# PIC32MK0512GPK064 device description
Architecture: MIPS; Family: PIC32MK; Series: PIC32MK
Registers are 32-bit, read-write, no defined reset value unless marked. A register's access mark holds for its fields unless they carry their own. Offsets are from the block's base; [hi:lo] are bit positions; lines under a group give offsets from that group; {n}, {i} and the like mark numbered series; 'fields as' and 'values as' point back to an identical list.

## SB
Instances: SB 0x1f8f0510 in periph_ssx
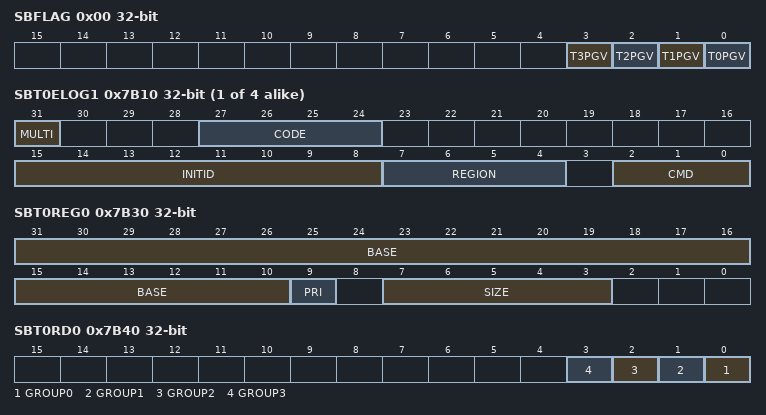
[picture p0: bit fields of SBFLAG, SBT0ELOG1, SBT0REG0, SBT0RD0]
0x00 SBFLAG ro — System Bus Status Flag Register
  [all] fields
    1=Target is reporting a Permission Group (PG) violation; 0=Target is not reporting a PG violation
  [3] T3PGV — Target 3 Permission Group Violation Status bits
  [2] T2PGV — Target 2 Permission Group Violation Status bits
  [1] T1PGV — Target 1Permission Group Violation Status bits
  [0] T0PGV — Target 0 Permission Group Violation Status bits
{0x7B10+0x400*i} SBT{i}ELOG1 ro (i=0..3) — System Bus Target 'x' Error Log Register 1
  [31] MULTI — Multiple Permission Violations Status bit
    1=Multiple errors have been detected; 0=No multiple errors have been detected
  [27:24] CODE — Error Code bits
    3=Permission violation; 0=No error
  [15:8] INITID — Initiator ID of Requester bits
    {v}=CAN{v-9} (v=10..13); 9=USB2; 8=USB1; 7=ADC0-ADC5, ADC7; 5=Flash Controller; 4=DMA Read (DMAPRI (CFGCON) = 1); 3=DMA Read (DMAPRI (CFGCON) = 0); 2=CPU (CPUPRI (CFGCON) = 1); 1=CPU (CPUPRI (CFGCON) = 0)
  [7:4] REGION — Requested Region Number bits
    {v}=Target region {v} reported a permission group violation (v=0..15)
  [2:0] CMD — Transaction Command of the Requester bits
    5=Write (a non-posted write); 3=Read (a locked read caused by a Read-Modify-Write transaction); 2=Read; 1=Write; 0=Idle
{0x7B14+0x400*i} SBT{i}ELOG2 ro (i=0..3) — System Bus Target 'x' Error Log Register 2
  [1:0] GROUP — Requested Permissions Group bits
    1=Group 1; 0=Group 0 (default group of CPU at Reset)
{0x7B18+0x400*i} SBT{i}ECON (i=0..3) — System Bus Target 'x' Error Control Register
  [24] ERRP — Error Control bit
    1=Report protection group violation errors; 0=Do not report protection group violation errors
{0x7B20+0x400*i} SBT{i}ECLRS ro (i=0..3) — System Bus Target 'x' Single Error Clear Register
  [0] CLEAR
{0x7B28+0x400*i} SBT{i}ECLRM ro (i=0..3) — System Bus Target 'x' Multiple Error Clear Register
  [0] CLEAR
0x7B30 SBT0REG0
  [31:10] BASE
  [9] PRI — Region Priority Level bit
    1=Level 2; 0=Level 1
  [7:3] SIZE — Region Size bits
    30=Region size is 549755813888 bytes; 29=Region size is 274877906944 bytes; 28=Region size is 137438953472 bytes; 27=Region size is 68719476736 bytes; 26=Region size is 34359738368 bytes; 25=Region size is 17179869184 bytes; 24=Region size is 8589934592 bytes; 23=Region size is 4294967296 bytes; 22=Region size is 2147483648 bytes; 21=Region size is 1073741824 bytes; 20=Region size is 536870912 bytes; 19=Region size is 268435456 bytes; 18=Region size is 134217728 bytes; 17=Region size is 67108864 bytes; 16=Region size is 33554432 bytes; 15=Region size is 16777216 bytes; 14=Region size is 8388608 bytes; 13=Region size is 4194304 bytes; 12=Region size is 2097152 bytes; 11=Region size is 1048576 bytes; 10=Region size is 524288 bytes; 9=Region size is 262144 bytes; 8=Region size is 131072 bytes; 7=Region size is 65536 bytes; 6=Region size is 32768 bytes; 5=Region size is 16384 bytes; 4=Region size is 8192 bytes; 3=Region size is 4096 bytes; 2=Region size is 2048 bytes; 1=Region size is 1024 bytes; 0=Region is not present
0x7B40 SBT0RD0
  [n] GROUP{n} (n=0..3) — Group{n} Read Permissions bits
    1=Privilege Group {n} has read permission; 0=Privilege Group {n} does not have read permission
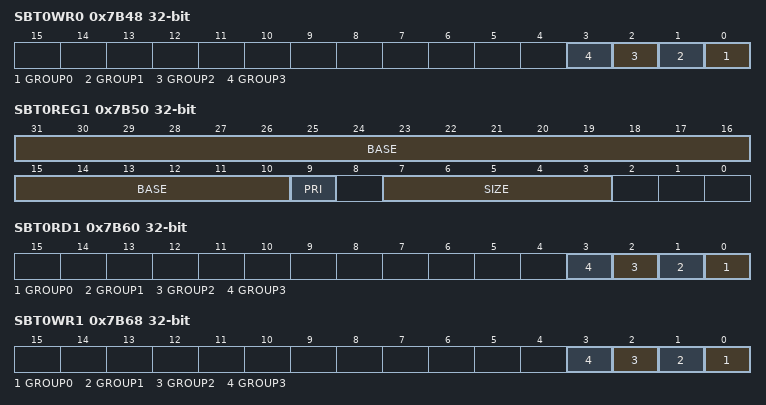
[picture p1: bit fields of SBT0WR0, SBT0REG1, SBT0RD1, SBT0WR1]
0x7B48 SBT0WR0
  [n] GROUP{n} (n=0..3) — Group {n} Write Permissions bits
    1=Privilege Group {n} has write permission; 0=Privilege Group {n} does not have write permission
0x7B50 SBT0REG1
  fields as SBT0REG0
0x7B60 SBT0RD1
  fields as SBT0RD0
0x7B68 SBT0WR1
  fields as SBT0WR0
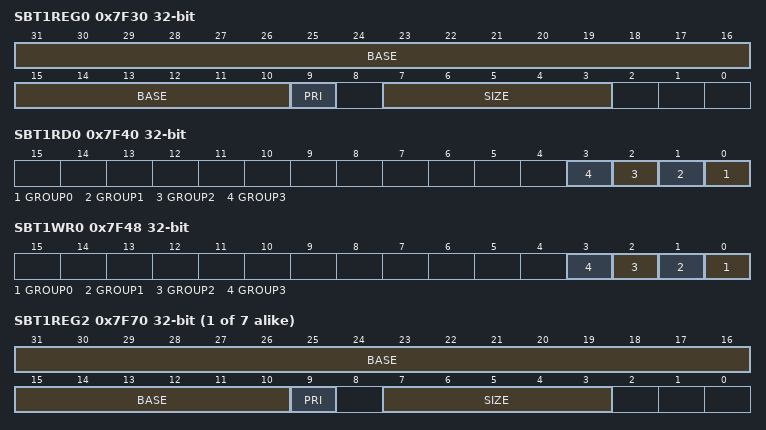
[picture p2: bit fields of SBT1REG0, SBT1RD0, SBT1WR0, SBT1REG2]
0x7F30 SBT1REG0
  fields as SBT0REG0
0x7F40 SBT1RD0
  fields as SBT0RD0
0x7F48 SBT1WR0
  fields as SBT0WR0
{0x7F30+0x20*i} SBT1REG{i} (i=2..8)
  fields as SBT0REG0
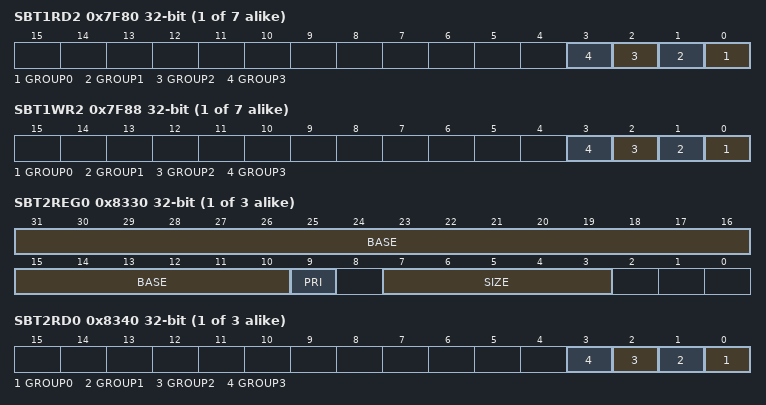
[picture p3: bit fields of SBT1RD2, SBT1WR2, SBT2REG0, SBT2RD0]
{0x7F40+0x20*i} SBT1RD{i} (i=2..8)
  fields as SBT0RD0
{0x7F48+0x20*i} SBT1WR{i} (i=2..8)
  fields as SBT0WR0
{0x8330+0x20*i} SBT2REG{i} (i=0..2)
  fields as SBT0REG0
{0x8340+0x20*i} SBT2RD{i} (i=0..2)
  fields as SBT0RD0
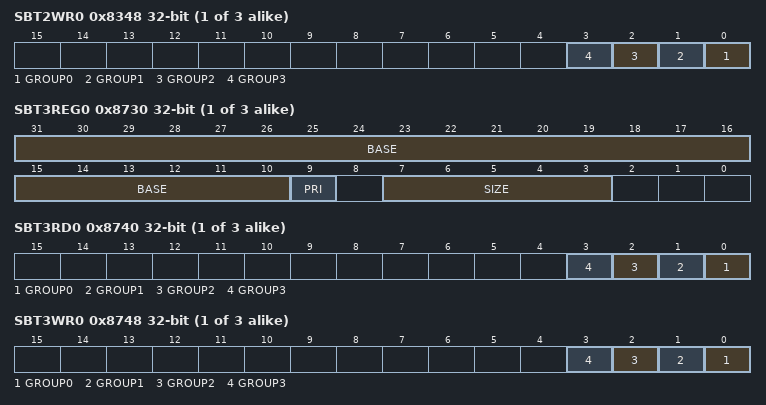
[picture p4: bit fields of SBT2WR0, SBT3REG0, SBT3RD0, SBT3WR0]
{0x8348+0x20*i} SBT2WR{i} (i=0..2)
  fields as SBT0WR0
{0x8730+0x20*i} SBT3REG{i} (i=0..2)
  fields as SBT0REG0
{0x8740+0x20*i} SBT3RD{i} (i=0..2)
  fields as SBT0RD0
{0x8748+0x20*i} SBT3WR{i} (i=0..2)
  fields as SBT0WR0

## Notices in the file
Copyright (c) 2019 Microchip Technology Inc.
SPDX-License-Identifier: Apache-2.0
Licensed under the Apache License, Version 2.0 (the "License");
you may not use this file except in compliance with the License.
You may obtain a copy of the License at
http://www.apache.org/licenses/LICENSE-2.0
Unless required by applicable law or agreed to in writing, software
distributed under the License is distributed on an "AS IS" BASIS,
WITHOUT WARRANTIES OR CONDITIONS OF ANY KIND, either express or implied.
See the License for the specific language governing permissions and
limitations under the License.
